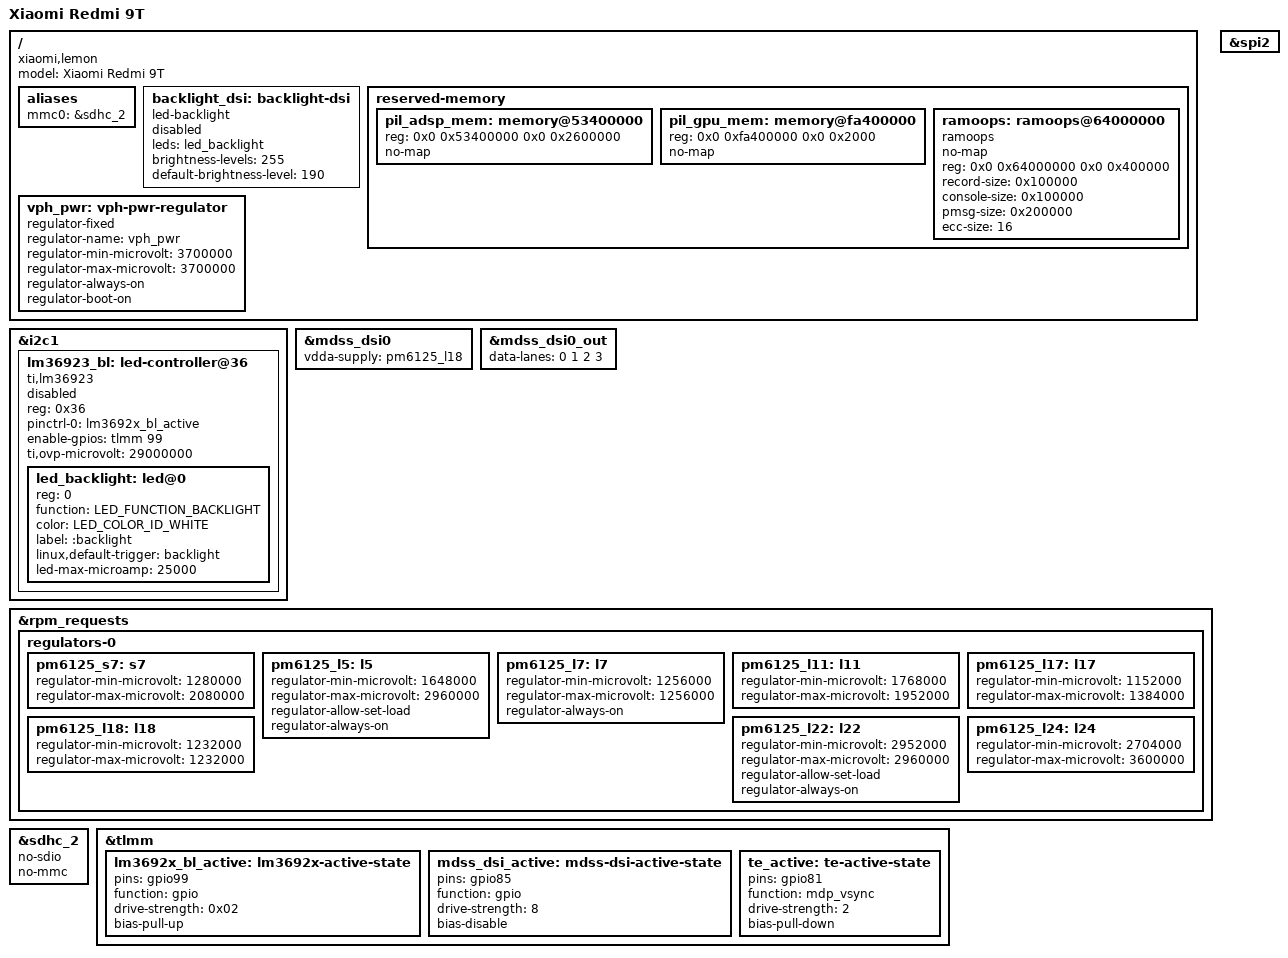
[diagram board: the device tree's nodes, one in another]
// SPDX-License-Identifier: (GPL-2.0+ OR BSD-3-Clause)
/*
 * Copyright (c) 2026 Adam Skladowski <a39skl@gmail.com>
 */

/dts-v1/;

#include <dt-bindings/leds/common.h>
#include "sm6115-xiaomi-lime-common.dtsi"

/ {
	model = "Xiaomi Redmi 9T";
	compatible = "xiaomi,lemon", "qcom,sm6115";

	aliases {
		mmc0 = &sdhc_2;
	};

	backlight_dsi: backlight-dsi {
		compatible = "led-backlight";
		leds = <&led_backlight>;
		brightness-levels = <255>;
		default-brightness-level = <190>;
		/* Backlight controllers can differ between panel variants */
		status = "disabled";
	};

	reserved-memory {
		pil_adsp_mem: memory@53400000 {
			reg = <0x0 0x53400000 0x0 0x2600000>;
			no-map;
		};

		pil_gpu_mem: memory@fa400000 {
			reg = <0x0 0xfa400000 0x0 0x2000>;
			no-map;
		};

		ramoops: ramoops@64000000 {
			compatible = "ramoops";
			no-map;
			reg = <0x0 0x64000000 0x0 0x400000>;
			record-size = <0x100000>;
			console-size = <0x100000>;
			pmsg-size = <0x200000>;
			ecc-size = <16>;
		};
	};

	vph_pwr: vph-pwr-regulator {
		compatible = "regulator-fixed";
		regulator-name = "vph_pwr";
		regulator-min-microvolt = <3700000>;
		regulator-max-microvolt = <3700000>;

		regulator-always-on;
		regulator-boot-on;
	};
};

&i2c1 {
	status = "okay";

	lm36923_bl: led-controller@36 {
		compatible = "ti,lm36923";
		reg = <0x36>;

		pinctrl-0 = <&lm3692x_bl_active>;
		pinctrl-names = "default";

		enable-gpios = <&tlmm 99 GPIO_ACTIVE_HIGH>;
		ti,ovp-microvolt = <29000000>;
		/* Backlight controllers can differ between panel variants */
		status = "disabled";

		#address-cells = <1>;
		#size-cells = <0>;

		led_backlight: led@0 {
			reg = <0>;
			function = LED_FUNCTION_BACKLIGHT;
			color = <LED_COLOR_ID_WHITE>;
			label = ":backlight";
			linux,default-trigger = "backlight";
			led-max-microamp = <25000>;
		};
	};
};

&mdss_dsi0 {
	vdda-supply = <&pm6125_l18>;
};

&mdss_dsi0_out {
	data-lanes = <0 1 2 3>;
};

&rpm_requests {
	regulators-0 {
		pm6125_s7: s7 {
			regulator-min-microvolt = <1280000>;
			regulator-max-microvolt = <2080000>;
		};

		pm6125_l5: l5 {
			regulator-min-microvolt = <1648000>;
			regulator-max-microvolt = <2960000>;
			regulator-allow-set-load;

			regulator-always-on;
		};

		pm6125_l7: l7 {
			/* sdhci2 vdd-io-bias supply */
			regulator-min-microvolt = <1256000>;
			regulator-max-microvolt = <1256000>;

			regulator-always-on;
		};

		pm6125_l11: l11 {
			regulator-min-microvolt = <1768000>;
			regulator-max-microvolt = <1952000>;
		};

		pm6125_l17: l17 {
			regulator-min-microvolt = <1152000>;
			regulator-max-microvolt = <1384000>;
		};

		pm6125_l18: l18 {
			regulator-min-microvolt = <1232000>;
			regulator-max-microvolt = <1232000>;
		};

		pm6125_l22: l22 {
			regulator-min-microvolt = <2952000>;
			regulator-max-microvolt = <2960000>;
			regulator-allow-set-load;

			regulator-always-on;
		};

		pm6125_l24: l24 {
			regulator-min-microvolt = <2704000>;
			regulator-max-microvolt = <3600000>;
		};
	};
};

&sdhc_2 {
	/* No binding for vdd-io-bias on L7*/
	no-sdio;
	no-mmc;
};

&spi2 {
	status = "okay";
};

&tlmm {
	lm3692x_bl_active: lm3692x-active-state {
		pins = "gpio99";
		function = "gpio";
		drive-strength = <0x02>;
		bias-pull-up;
	};

	mdss_dsi_active: mdss-dsi-active-state {
		pins = "gpio85";
		function = "gpio";
		drive-strength = <8>;
		bias-disable;
	};

	te_active: te-active-state {
		pins = "gpio81";
		function = "mdp_vsync";
		drive-strength = <2>;
		bias-pull-down;
	};
};
